# EFR32MR21A020F512IM32 register map
Vendor: Silicon Labs; Series: EFR32; File version: D
Registers are 32-bit, read-write, reset 0x0 unless marked. A register's access mark holds for its fields unless they carry their own. Offsets are from the block's base; [hi:lo] are bit positions; {n}, {i} and the like mark numbered series; 'fields as' and 'values as' point back to an identical list.

## BUFC_NS — BUFC_NS Registers
Base 0x54004000
Same registers: BUFC_S 0x44004000
0x00 IPVERSION ro
0x04 EN
  [0] EN — Enable peripheral clock to this module
{0x8+0x30*i} BUF{i}_CTRL (i=0..3)
  [2:0] SIZE — Buffer Size
    0=Sets Buffer size to 64 bytes; 1=Sets Buffer size to 128 bytes; 2=Sets Buffer size to 256 bytes; 3=Sets Buffer size to 512 bytes; 4=Sets Buffer size to 1024 bytes; 5=Sets Buffer size to 2048 bytes; 6=Sets Buffer size to 4096 bytes
{0xC+0x30*i} BUF{i}_ADDR (i=0..3)
  [23:0] ADDR — Buffer Address
{0x10+0x30*i} BUF{i}_WRITEOFFSET (i=0..3)
  [12:0] WRITEOFFSET
{0x14+0x30*i} BUF{i}_READOFFSET (i=0..3)
  [12:0] READOFFSET
{0x1C+0x30*i} BUF{i}_READDATA ro (i=0..3)
  [7:0] READDATA — Buffer Read Data
{0x20+0x30*i} BUF{i}_WRITEDATA wo (i=0..3)
  [7:0] WRITEDATA — Buffer Write Data
{0x24+0x30*i} BUF{i}_XWRITE wo (i=0..3)
  [7:0] XORWRITEDATA — Buffer XOR Write Data
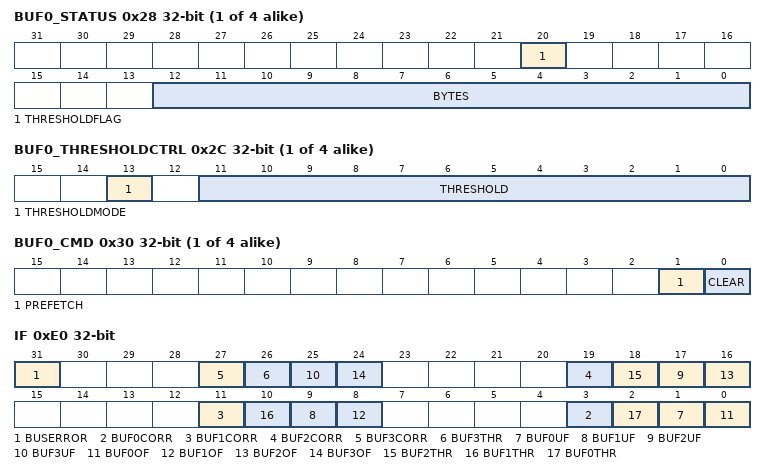
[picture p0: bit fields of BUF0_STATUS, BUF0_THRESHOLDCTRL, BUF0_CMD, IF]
{0x28+0x30*i} BUF{i}_STATUS ro (i=0..3)
  [20] THRESHOLDFLAG — Buffer Threshold Flag
  [12:0] BYTES — Number of Bytes in the Buffer
{0x2C+0x30*i} BUF{i}_THRESHOLDCTRL (i=0..3)
  [13] THRESHOLDMODE — Buffer Threshold Mode
    0=LARGER (THRESHOLDIF will be set if BYTES is larger than THRESHOLD); 1=LESSOREQUAL (THRESHOLDIF will be set if BYTES is less than or equal to THRESHOLD)
  [11:0] THRESHOLD — Buffer Threshold Value
{0x30+0x30*i} BUF{i}_CMD wo (i=0..3)
  [1] PREFETCH
  [0] CLEAR — Buffer Clear
{0x34+0x30*i} BUF{i}_FIFOASYNC wo (i=0..3)
  [0] RST — Reset ASYNC
0xE0 IF
  [31] BUSERROR
  [8n+3] BUF{n}CORR (n=0..3) — Buffer {n} Corrupt
  [26] BUF3THR — Buffer 3 Threshold Event
  [8n+1] BUF{n}UF (n=0..3) — Buffer {n} Underflow
  [8n] BUF{n}OF (n=0..3) — Buffer {n} Overflow
  [18] BUF2THR — Buffer 2 Threshold Event
  [10] BUF1THR — Buffer 2 Threshold Event
  [2] BUF0THR — Buffer 0 Threshold Event
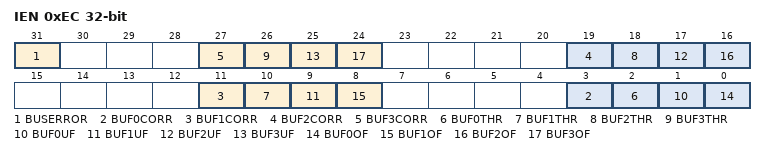
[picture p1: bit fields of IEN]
0xEC IEN
  [31] BUSERROR — BUSERROR Interrupt Enable
  [8n+3] BUF{n}CORR (n=0..3) — BUF{n}CORR Interrupt Enable
  [8n+2] BUF{n}THR (n=0..3) — BUF{n}THR Interrupt Enable
  [8n+1] BUF{n}UF (n=0..3) — BUF{n}UF Interrupt Enable
  [8n] BUF{n}OF (n=0..3) — BUF{n}OF Interrupt Enable
0xF0 RAMBASEADDR reset 0x20000000
  [31:16] RAMBASEADDR

## BURAM_NS — BURAM_NS Registers
Base 0x50080000
Same registers: BURAM_S 0x40080000
{0x0+4i} RET{i}_REG (i=0..31)
  [31:0] RETREG — Latch based Retention register

## BURTC_NS — BURTC_NS Registers
Base 0x50064000
Same registers: BURTC_S 0x40064000
0x00 IPVERSION ro
  [31:0] IPVERSION — IP Version ID
0x04 EN
  [0] EN — BURTC Enable
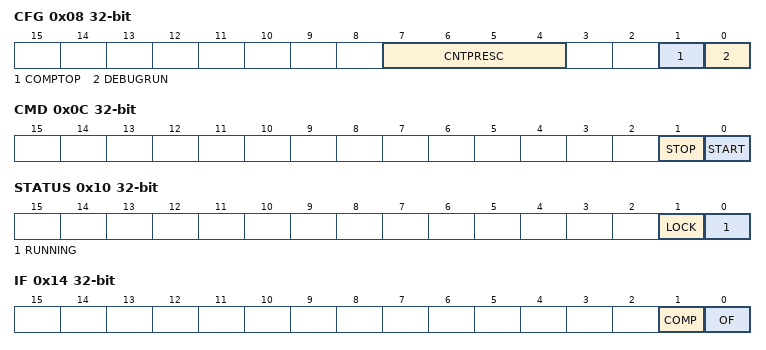
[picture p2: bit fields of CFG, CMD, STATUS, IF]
0x08 CFG
  [7:4] CNTPRESC — Counter prescaler value.
    0=DIV1 (CLK_CNT = (BURTC LF CLK)/1); 1=DIV2 (CLK_CNT = (BURTC LF CLK)/2); 2=DIV4 (CLK_CNT = (BURTC LF CLK)/4); 3=DIV8 (CLK_CNT = (BURTC LF CLK)/8); 4=DIV16 (CLK_CNT = (BURTC LF CLK)/16); 5=DIV32 (CLK_CNT = (BURTC LF CLK)/32); 6=DIV64 (CLK_CNT = (BURTC LF CLK)/64); 7=DIV128 (CLK_CNT = (BURTC LF CLK)/128); 8=DIV256 (CLK_CNT = (BURTC LF CLK)/256); 9=DIV512 (CLK_CNT = (BURTC LF CLK)/512); 10=DIV1024 (CLK_CNT = (BURTC LF CLK)/1024); 11=DIV2048 (CLK_CNT = (BURTC LF CLK)/2048); 12=DIV4096 (CLK_CNT = (BURTC LF CLK)/4096); 13=DIV8192 (CLK_CNT = (BURTC LF CLK)/8192); 14=DIV16384 (CLK_CNT = (BURTC LF CLK)/16384); 15=DIV32768 (CLK_CNT = (BURTC LF CLK)/32768)
  [1] COMPTOP — Compare Channel is Top Value
    0=DISABLE (The top value of the BURTC is 4294967295 (0xFFFFFFFF)); 1=ENABLE (The top value of the BURTC is given by COMP)
  [0] DEBUGRUN — Debug Mode Run Enable
    0=DISABLE (BURTC is frozen in debug mode); 1=ENABLE (BURTC is running in debug mode)
0x0C CMD wo
  [1] STOP — Stop BURTC counter
  [0] START — Start BURTC counter
0x10 STATUS ro
  [1] LOCK — Configuration Lock Status
    0=UNLOCKED (All BURTC lockable registers are unlocked.); 1=LOCKED (All BURTC lockable registers are locked.)
  [0] RUNNING — BURTC running status
0x14 IF
  [1] COMP — Compare Match Interrupt Flag
  [0] OF — Overflow Interrupt Flag
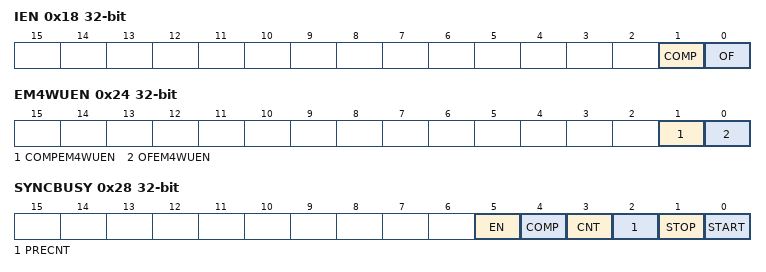
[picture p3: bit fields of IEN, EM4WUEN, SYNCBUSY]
0x18 IEN
  fields as IF
0x1C PRECNT
  [14:0] PRECNT — Pre-Counter Value
0x20 CNT
  [31:0] CNT — Counter Value
0x24 EM4WUEN
  [1] COMPEM4WUEN — Compare Match EM4 Wakeup Enable
  [0] OFEM4WUEN — Overflow EM4 Wakeup Enable
0x28 SYNCBUSY ro
  [5] EN — Sync busy for EN
  [4] COMP — Sync busy for COMP
  [3] CNT — Sync busy for CNT
  [2] PRECNT — Sync busy for PRECNT
  [1] STOP — Sync busy for STOP
  [0] START — Sync busy for START
0x2C LOCK wo reset 0xAEE8
  [15:0] LOCKKEY — Configuration Lock Key
    0xAEE8=UNLOCK (Write to unlock all BURTC lockable registers)
0x30 COMP
  [31:0] COMP — Compare Value
